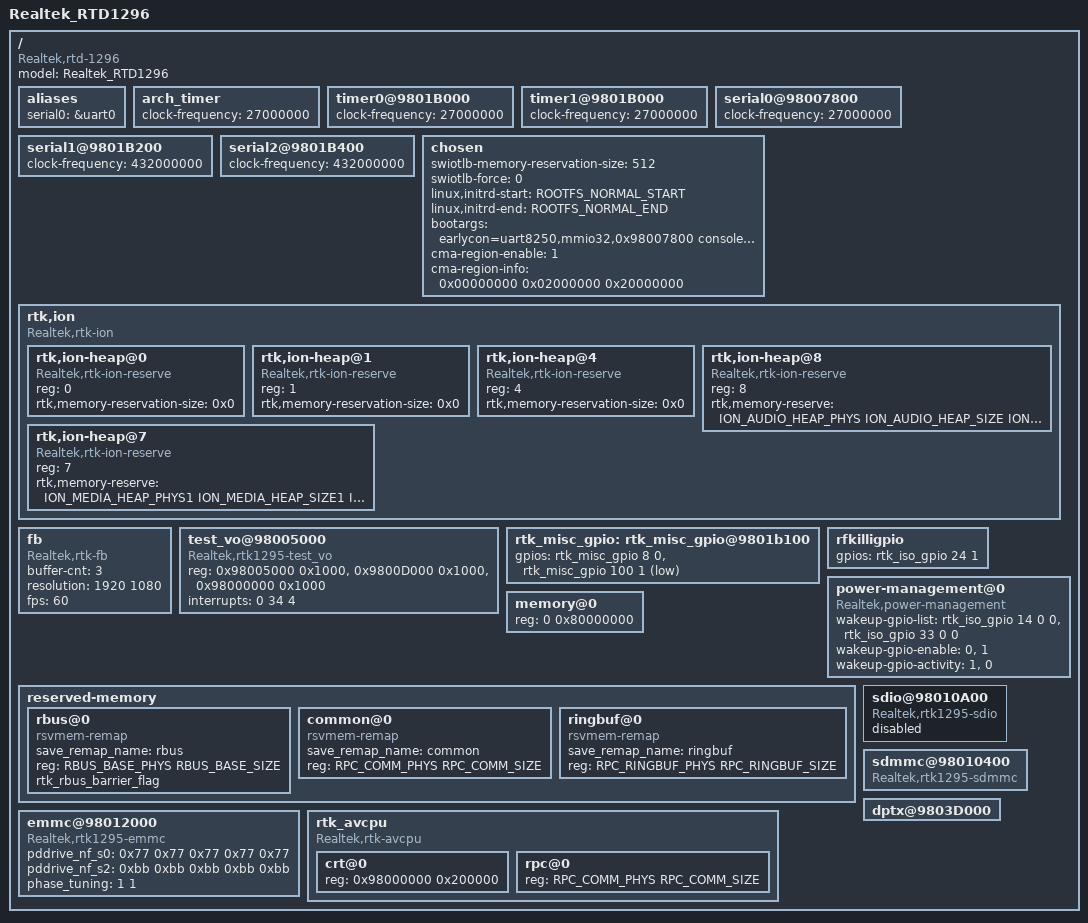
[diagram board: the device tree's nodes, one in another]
/dts-v1/;
#include <dt-bindings/soc/rtd129x,memory.h>

/* 0x00000000 ~ 0x0002ffff */
/memreserve/ SYS_BOOTCODE_MEMBASE SYS_BOOTCODE_MEMSIZE;
 /* 0x0001f000 ~ 0x0001ffff */
/memreserve/ RPC_COMM_PHYS RPC_COMM_SIZE ;
/* 0x01ffe000 ~ 0x02001fff */
/memreserve/ RPC_RINGBUF_PHYS RPC_RINGBUF_SIZE;
/* 0x02200000 ~ 0x025fffff */
/memreserve/ ROOTFS_NORMAL_START ROOTFS_NORMAL_SIZE;
/* 0x02600000 ~ 0x031fffff */
/memreserve/ ION_AUDIO_HEAP_PHYS ION_AUDIO_HEAP_SIZE ;
/* 0x03200000 ~ 0x0e9fffff */
/memreserve/ ION_MEDIA_HEAP_PHYS1  ION_MEDIA_HEAP_SIZE1;
/* 0x10000000 ~ 0x10013fff */
/memreserve/ ACPU_IDMEM_PHYS ACPU_IDMEM_SIZE;
 /* 0x11000000 ~ 0x181fffff */
/memreserve/ ION_MEDIA_HEAP_PHYS2 ION_MEDIA_HEAP_SIZE2	;

#include "rtd-1296.dtsi"

/ {
	model= "Realtek_RTD1296";
	compatible = "Realtek,rtd-1296";

	aliases {
		serial0 = &uart0;
	};

	arch_timer {
		clock-frequency = <27000000>;
	};

	timer0@9801B000 {
		clock-frequency = <27000000>;
	};

	timer1@9801B000 {
		clock-frequency = <27000000>;
	};

	serial0@98007800 {
		clock-frequency = <27000000>;
	};

	serial1@9801B200 {
		clock-frequency = <432000000>;
	};

	serial2@9801B400 {
		clock-frequency = <432000000>;
	};

	chosen {
		swiotlb-memory-reservation-size = <512>;
		swiotlb-force = <0>;
	};

	rtk,ion {
		compatible = "Realtek,rtk-ion";
		#address-cells = <1>;
		#size-cells = <0>;

		rtk,ion-heap@0 { /* SYSTEM_HEAP */
			compatible = "Realtek,rtk-ion-reserve";
			reg = <0>;
			rtk,memory-reservation-size = <0x0>;
		};

		rtk,ion-heap@1 { /* System contig */
			compatible = "Realtek,rtk-ion-reserve";
			reg = <1>;
			rtk,memory-reservation-size = <0x0>;
		};

		rtk,ion-heap@4 { /* DMA_HEAP */
			compatible = "Realtek,rtk-ion-reserve";
			reg = <4>;
			rtk,memory-reservation-size = <0x0>;
		};

		rtk,ion-heap@8 { /* Audio */
			compatible = "Realtek,rtk-ion-reserve";
			reg = <8>;
		};

		rtk,ion-heap@7 { /* TYPE_MEDIA */
			compatible = "Realtek,rtk-ion-reserve";
			reg = <7>;
		};
	};

	fb {
		compatible = "Realtek,rtk-fb";
		buffer-cnt = <3>;
		resolution = <1920 1080>;
		fps = <60>;
	};

	test_vo@98005000 {
		compatible = "Realtek,rtk1295-test_vo";
		reg = <0x98005000 0x1000>,
			<0x9800D000 0x1000>,
			<0x98000000 0x1000>;
		interrupts = <0 34 4>;
	};

	rtk_misc_gpio: rtk_misc_gpio@9801b100 {
		gpios = <&rtk_misc_gpio 8 0 0>, /* install button */
			<&rtk_misc_gpio 100 1 1>; /* audio dac unmute */
	};

	rfkilligpio{
		gpios = <&rtk_iso_gpio 24 1 0>; /* bt power */
		status = "okay";
	};

	/*
	 * Suspend GPIO control
	 *
	 * [wakeup-gpio-list]
	 * rtk_iso_gpio 14: BT wakeup host pin
	 * rtk_iso_gpio 33: WiFi wakeup host pin
	 *
	 * [wakeup-gpio-enable]
	 * Wakeup from BT: <0>disabele
	 * Wakeup from WiFi: <1> enable
	 *
	 * [wakeup-gpio-activity]
	 * BT pin: <1>active high
	 * WIFI pin: <0>active low
	 */
	power-management@0  {
		compatible = "Realtek,power-management";
		wakeup-gpio-list = <&rtk_iso_gpio 14 0 0>,
			<&rtk_iso_gpio 33 0 0>;
		wakeup-gpio-enable = <0>, <1>;
		wakeup-gpio-activity =<1>, <0>;
	};
};


/ {
	chosen {
		linux,initrd-start = <ROOTFS_NORMAL_START>;
		linux,initrd-end = <ROOTFS_NORMAL_END>;
		bootargs = "earlycon=uart8250,mmio32,0x98007800 console=ttyS0,115200 init=/init androidboot.hardware=kylin androidboot.storage=emmc loglevel=4";
	};

	/*
	 * NOTE:
	 * <flag size base>
	 * flag: reserved
	 * size: unit is byte
	 * base: unit is byte
	 *
	 * Array size not over 8;
	 * You may change the max array size in KConfig,
	 * max CMA array size is CONFIG_CMA_AREAS+1.
	 *
	 * If cma-region-enable is enabled<1>,
	 * kernel driver will use cma-region-info to initial CMA memory.
	 *
	 * If cma-region-enable is disabled<0>,
	 * kernel driver will use cma= to initial CMA memory.
	 *
	 * if both setting is loaded, cma-region-info had higher priority.
	 */
	chosen {
		cma-region-enable = <1>;
		cma-region-info = <0x00000000 0x02000000 0x20000000>;
		/*cma-region-info = <0x00000000 0x01000000 0x12c00000>,
			<0x00000000 0x12c00000 0x20000000>;*/
	};

	memory@0 {
		device_type = "memory";
		reg = <0 0x80000000>; /* 2048 MB */
	};

	reserved-memory {
		#address-cells = <1>;
		#size-cells = <1>;
		ranges;

		rbus@0 {
			compatible = "rsvmem-remap";
			save_remap_name = "rbus";
			reg = <RBUS_BASE_PHYS RBUS_BASE_SIZE>;
			rtk_rbus_barrier_flag;
		};

		common@0 {
			compatible = "rsvmem-remap";
			save_remap_name = "common";
			reg = <RPC_COMM_PHYS RPC_COMM_SIZE>;
		};

		ringbuf@0 {
			compatible = "rsvmem-remap";
			save_remap_name = "ringbuf";
			reg = <RPC_RINGBUF_PHYS RPC_RINGBUF_SIZE>;
		};
	};

	rtk,ion {
		rtk,ion-heap@8 { /* Audio */
			compatible = "Realtek,rtk-ion-reserve";
			reg = <8>;
			rtk,memory-reserve = <
				ION_AUDIO_HEAP_PHYS
				ION_AUDIO_HEAP_SIZE
				ION_AUDIO_HEAP_FLAG>;
		};

		rtk,ion-heap@7 { /* TYPE_MEDIA */
			compatible = "Realtek,rtk-ion-reserve";
			reg = <7>;
			rtk,memory-reserve = <
				ION_MEDIA_HEAP_PHYS1
				ION_MEDIA_HEAP_SIZE1
				ION_MEDIA_HEAP_FLAG1
				ION_MEDIA_HEAP_PHYS2
				ION_MEDIA_HEAP_SIZE2
				ION_MEDIA_HEAP_FLAG2>;
		};
	};

	/*
	 * pddrive_nf0, pddrive_nf1, pddrive_nf2, pddrive_nf3, pddrive_nf4 ; for sdr50
	 * pddrive_nf0, pddrive_nf1, pddrive_nf2, pddrive_nf3, pddrive_nf4 ; for hs200
	 */

	sdio@98010A00 {
		compatible = "Realtek,rtk1295-sdio";
		status = "disabled";
	};

	sdmmc@98010400 {
		compatible = "Realtek,rtk1295-sdmmc";
		status = "okay"; 
		/* status = "disabled"; */
	};

	emmc@98012000 {
		compatible = "Realtek,rtk1295-emmc";
		pddrive_nf_s0 = <0x77 0x77 0x77 0x77 0x77>;
		pddrive_nf_s2 = <0xbb 0xbb 0xbb 0xbb 0xbb>;
		phase_tuning = <1 1>; /* BPI arg0: tx tuning switch, arg1: rx tuning switch*/
	};

	dptx@9803D000 {
		status = "okay"; 
		/* status = "disabled"; */
	};

	rtk_avcpu {
		compatible = "Realtek,rtk-avcpu";
		#address-cells = <1>;
		#size-cells = <1>;
		ranges;

		crt@0 {
			reg = <0x98000000 0x200000>;
		};

		rpc@0 {
			reg = <RPC_COMM_PHYS RPC_COMM_SIZE>;
		};
	};
};

